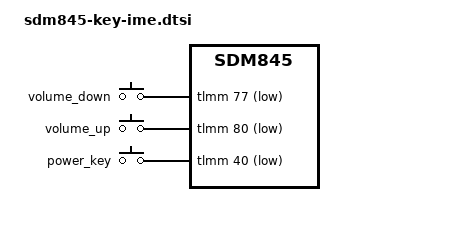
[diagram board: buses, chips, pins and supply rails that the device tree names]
&soc {
	gpio_keys {
		status = "disabled";
	};
};

&soc {
	htc_gpio_keys {
		compatible = "gpio-keys";
		label = "gpio-keys";

		pinctrl-names = "default";
		pinctrl-0 = <&gpio_key_default>;

		vol_down {
			label = "volume_down";
			gpios = <&tlmm 77 GPIO_ACTIVE_LOW>;
			linux,input-type = <1>;
			linux,code = <114>;
			gpio-key,wakeup;
			debounce-interval = <0>;
		};

		vol_up {
			label = "volume_up";
			gpios = <&tlmm 80 GPIO_ACTIVE_LOW>;
			linux,input-type = <1>;
			linux,code = <115>;
			gpio-key,wakeup;
			debounce-interval = <0>;
		};

		power_key {
			label = "power_key";
			gpios = <&tlmm 40 GPIO_ACTIVE_LOW>;
			linux,input-type = <1>;
			linux,code = <116>;
			gpio-key,wakeup;
			debounce-interval = <0>;
		};
	};
};

&tlmm {
	tlmm_gpio_key {
		gpio_key_default: gpio_key_default {
			mux {
				pins = "gpio40", "gpio77", "gpio80";
				function = "gpio";
			};
			config {
				pins = "gpio40", "gpio77", "gpio80";
				drive-strength = <2>;
				bias-disable;
			};
		};
	};
};

&pm8998_gpios {
	/delete-node/ key_home;
	/delete-node/ key_vol_up;
	/delete-node/ key_cam_snapshot;
	/delete-node/ key_cam_focus;
};
